AUTOSAR XML (schema 00050)
standard types defined: Boolean
package /ARRoot
  application-sw-component-type:
    provide port BlindSpotDetection
    provide port Defogger
    provide port Display
    require port Sensor
    behavior SideMirrorIB
      4 x runnable:
        BlindSpotDetectionRunnable: synchronous-server-call-point
        DefoggerRunnable: synchronous-server-call-point
        DisplayRunnable: variable-access
        SensorRunnable: variable-access
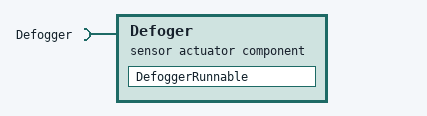
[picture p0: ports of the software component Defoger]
  sensor actuator sw component type Defoger
    require port Defogger
    behavior DefoggerIB
      runnable DefoggerRunnable: synchronous-server-call-point=Defogger.
  client server interface Defogger: client-server-operation=arguments=argument-data-prototype=type=Boolean
  swc implementation DefoggerIMP: programming-language=C, behavior=DefoggerIB
  swc implementation DisplayIMP: programming-language=C, behavior=DisplayIB
